# ADuCM355 register map
Vendor: Analog Devices; Series: ADuCM355; File version: 1p0
CPU: CM3 r0p1, little endian, no MPU, no FPU, 3 interrupt priority bits
Registers are 32-bit, read-write, reset 0x0 unless marked. A register's access mark holds for its fields unless they carry their own. Offsets are from the block's base; [hi:lo] are bit positions; {n}, {i} and the like mark numbered series.

## BUSM0 — Bus matrix
Base 0x4004C800
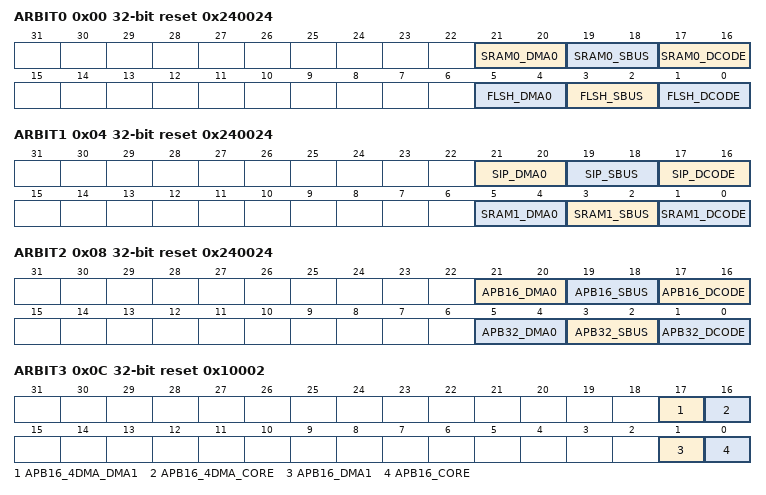
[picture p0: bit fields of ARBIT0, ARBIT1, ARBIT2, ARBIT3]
0x00 ARBIT0 reset 0x240024 — Arbitration Priority Configuration for FLASH and SRAM0
  [21:20] SRAM0_DMA0 range 0x00000000..0x00000003 — SRAM0 priority for DMA0
  [19:18] SRAM0_SBUS range 0x00000000..0x00000003 — SRAM0 priority for SBUS
  [17:16] SRAM0_DCODE range 0x00000000..0x00000003 — SRAM0 priority for Dcode
  [5:4] FLSH_DMA0 range 0x00000000..0x00000003 — Flash priority for DMA0
  [3:2] FLSH_SBUS range 0x00000000..0x00000003 — Flash priority for SBUS
  [1:0] FLSH_DCODE range 0x00000000..0x00000003 — Flash priority for DCODE
0x04 ARBIT1 reset 0x240024 — Arbitration Priority Configuration for SRAM1 and SIP
  [21:20] SIP_DMA0 range 0x00000000..0x00000003 — SIP priority for DMA0
  [19:18] SIP_SBUS range 0x00000000..0x00000003 — SIP priority for SBUS
  [17:16] SIP_DCODE range 0x00000000..0x00000003 — SIP priority for DCODE
  [5:4] SRAM1_DMA0 range 0x00000000..0x00000003 — SRAM1 priority for DMA0
  [3:2] SRAM1_SBUS range 0x00000000..0x00000003 — SRAM1 priority for SBUS
  [1:0] SRAM1_DCODE range 0x00000000..0x00000003 — SRAM1 priority for Dcode
0x08 ARBIT2 reset 0x240024 — Arbitration Priority Configuration for APB32 and APB16
  [21:20] APB16_DMA0 range 0x00000000..0x00000003 — APB16 priority for DMA0
  [19:18] APB16_SBUS range 0x00000000..0x00000003 — APB16 priority for SBUS
  [17:16] APB16_DCODE range 0x00000000..0x00000003 — APB16 priority for DCODE
  [5:4] APB32_DMA0 range 0x00000000..0x00000003 — APB32 priority for DMA0
  [3:2] APB32_SBUS range 0x00000000..0x00000003 — APB32 priority for SBUS
  [1:0] APB32_DCODE range 0x00000000..0x00000003 — APB32 priority for DCODE
0x0C ARBIT3 reset 0x10002 — Arbitration Priority Configuration for APB16 priority for core and for DMA1
  [17] APB16_4DMA_DMA1 range 0x00000000..0x00000001 — APB16 for dma priority for DMA1
  [16] APB16_4DMA_CORE range 0x00000000..0x00000001 — APB16 for dma priority for CORE
  [1] APB16_DMA1 range 0x00000000..0x00000001 — APB16 priority for DMA1
  [0] APB16_CORE range 0x00000000..0x00000001 — APB16 priority for CORE

## AGPIO2
Base 0x400C0080
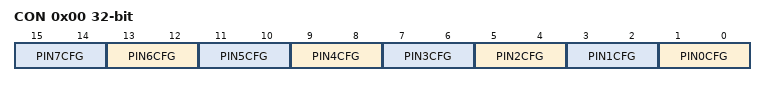
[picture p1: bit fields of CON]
0x00 CON — GPIO Port Configuration
  [2n+1:2n] PIN{n}CFG range 0x00000000..0x00000003 (n=0..7) — Pin {n} Configuration Bits
0x04 OEN 16-bit — GPIO Port Output Enable
  [15:0] OEN range 0x00000000..0x0000FFFF — Pin Output Drive enable
0x08 PE 16-bit reset 0xC0 — GPIO Port Pullup/Pulldown Enable
  [15:0] PE range 0x00000000..0x0000FFFF — Pin Pull enable
0x0C IEN 16-bit — GPIO Port Input Path Enable
  [15:0] IEN range 0x00000000..0x0000FFFF — Input path enable
0x10 IN 16-bit — GPIO Port Registered Data Input
  [15:0] IN ro — Registered data input
0x14 OUT 16-bit — GPIO Port Data Output
  [15:0] OUT range 0x00000000..0x0000FFFF — Data out
0x18 SET 16-bit — GPIO Port Data Out Set
  [15:0] SET wo range 0x00000000..0x0000FFFF — Set the output HIGH for the pin
0x1C CLR 16-bit — GPIO Port Data Out Clear
  [15:0] CLR wo range 0x00000000..0x0000FFFF — Set the output low for the port pin
0x20 TGL 16-bit — GPIO Port Pin Toggle
  [15:0] TGL wo range 0x00000000..0x0000FFFF — Toggle the output of the port pin

## AFECON
Base 0x400C0400
0x00 ADIID 16-bit — ADI Identification
  [15:0] ADIID ro — ADI Identifier.
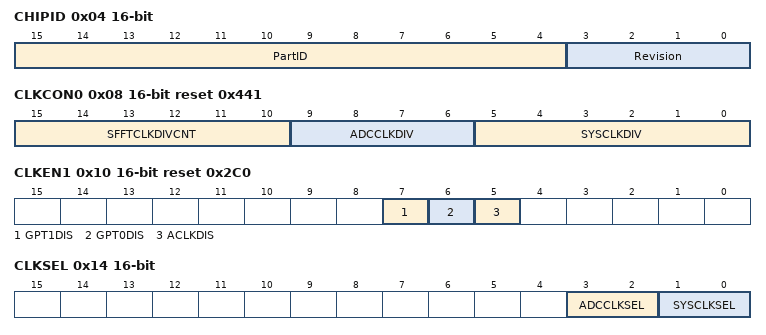
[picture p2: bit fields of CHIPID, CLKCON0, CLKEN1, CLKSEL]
0x04 CHIPID 16-bit — Chip Identification
  [15:4] PartID ro — Part Identifier
  [3:0] Revision ro — Silicon Revision Number
0x08 CLKCON0 16-bit reset 0x441 — Clock Divider Configuration
  [15:10] SFFTCLKDIVCNT range 0x00000000..0x0000003F — SFFT Clock Divider Configuration
  [9:6] ADCCLKDIV range 0x00000000..0x0000000F — ADC Clock Divider Configuration
  [5:0] SYSCLKDIV range 0x00000000..0x0000003F — System Clock Divider Configuration
0x10 CLKEN1 16-bit reset 0x2C0 — Clock Gate Enable
  [7] GPT1DIS — GPT1 Clock Enable
  [6] GPT0DIS — GPT0 Clock Enable
  [5] ACLKDIS — ACLK Clock Enable
0x14 CLKSEL 16-bit — Clock Select
  [3:2] ADCCLKSEL — Select ADC Clock Source
  [1:0] SYSCLKSEL — Select System Clock Source
0x1C GPIOCLKMUXSEL 16-bit — GPIO Clock MUX Select
  [2:0] SEL — Configure Clock MUX Out to GPIO
0x20 CLKCON0KEY 16-bit — Enable Clock Division to 8Mhz,4Mhz and 2Mhz
  [15:0] divsysclk_ulp_en
0x28 DIE2DIESTA 16-bit reset 0xABCD
  [15:0] STA range 0x00000000..0x0000FFFF — DIE2DIE Deadlock and Transaction Error Status
0x34 MKEY 16-bit
  [15:0] KEY wo range 0x00000000..0x0000FFFF — Key to Unlock SWRSTCON
0x38 DSPUPDATEEN 16-bit — DSP Update Enable
  [0] DSPLOOP — ADC Digital Logic Test
